# STM32F21x register map
File version: 1.0
CPU: 
Registers are 32-bit, read-write, reset 0x0 unless marked. A register's access mark holds for its fields unless they carry their own. Offsets are from the block's base; [hi:lo] are bit positions.

## Ethernet_PTP — Ethernet: Precision time protocol
Base 0x40028700
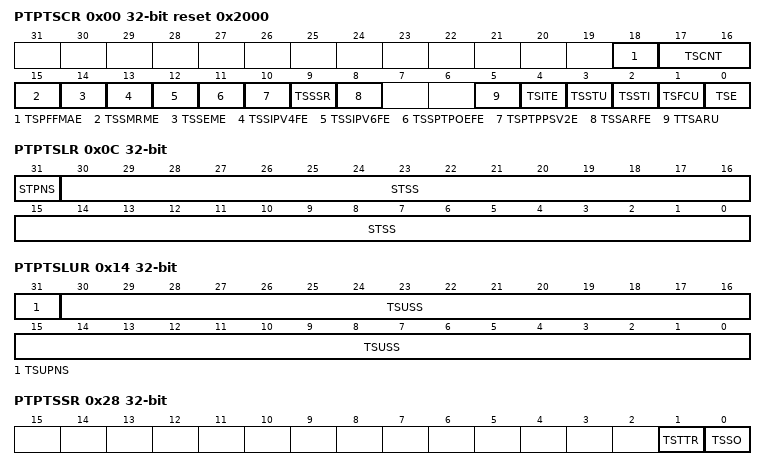
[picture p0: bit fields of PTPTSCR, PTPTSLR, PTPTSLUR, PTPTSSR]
0x00 PTPTSCR reset 0x2000 — Ethernet PTP time stamp control register
  [18] TSPFFMAE — Time stamp PTP frame filtering MAC address enable
  [17:16] TSCNT — Time stamp clock node type
  [15] TSSMRME — Time stamp snapshot for message relevant to master enable
  [14] TSSEME — Time stamp snapshot for event message enable
  [13] TSSIPV4FE — Time stamp snapshot for IPv4 frames enable
  [12] TSSIPV6FE — Time stamp snapshot for IPv6 frames enable
  [11] TSSPTPOEFE — Time stamp snapshot for PTP over ethernet frames enable
  [10] TSPTPPSV2E — Time stamp PTP packet snooping for version2 format enable
  [9] TSSSR — Time stamp subsecond rollover: digital or binary rollover control
  [8] TSSARFE — Time stamp snapshot for all received frames enable
  [5] TTSARU — Time stamp addend register update
  [4] TSITE — Time stamp interrupt trigger enable
  [3] TSSTU — Time stamp system time update
  [2] TSSTI — Time stamp system time initialize
  [1] TSFCU — Time stamp fine or coarse update
  [0] TSE — Time stamp enable
0x04 PTPSSIR — Ethernet PTP subsecond increment register
  [7:0] STSSI — System time subsecond increment
0x08 PTPTSHR ro — Ethernet PTP time stamp high register
  [31:0] STS — System time second
0x0C PTPTSLR ro — Ethernet PTP time stamp low register
  [31] STPNS — System time positive or negative sign
  [30:0] STSS — System time subseconds
0x10 PTPTSHUR — Ethernet PTP time stamp high update register
  [31:0] TSUS — Time stamp update second
0x14 PTPTSLUR — Ethernet PTP time stamp low update register
  [31] TSUPNS — Time stamp update positive or negative sign
  [30:0] TSUSS — Time stamp update subseconds
0x18 PTPTSAR — Ethernet PTP time stamp addend register
  [31:0] TSA — Time stamp addend
0x1C PTPTTHR — Ethernet PTP target time high register
  [31:0] TTSH — Target time stamp high
0x20 PTPTTLR — Ethernet PTP target time low register
  [31:0] TTSL — Target time stamp low
0x28 PTPTSSR ro — Ethernet PTP time stamp status register
  [1] TSTTR — Time stamp target time reached
  [0] TSSO — Time stamp second overflow
0x2C PTPPPSCR ro — Ethernet PTP PPS control register
  [3:0] PPSFREQ — PPS frequency selection

## Ethernet_DMA — Ethernet: DMA controller operation
Base 0x40029000
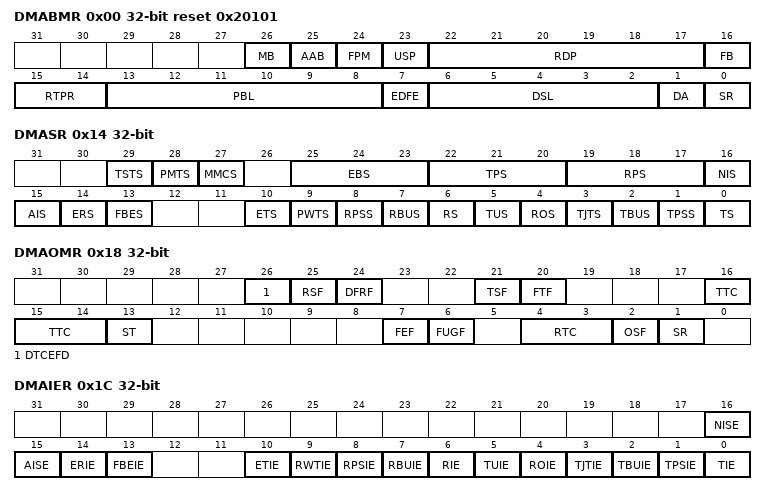
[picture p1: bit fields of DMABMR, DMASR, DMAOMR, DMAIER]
0x00 DMABMR reset 0x20101 — Ethernet DMA bus mode register
  [26] MB — Mixed burst
  [25] AAB — Address-aligned beats
  [24] FPM — 4xPBL mode
  [23] USP — Use separate PBL
  [22:17] RDP — Rx DMA PBL
  [16] FB — Fixed burst
  [15:14] RTPR — Rx Tx priority ratio
  [13:8] PBL — Programmable burst length
  [7] EDFE — Enhanced descriptor format enable
  [6:2] DSL — Descriptor skip length
  [1] DA — DMA Arbitration
  [0] SR — Software reset
0x04 DMATPDR — Ethernet DMA transmit poll demand register
  [31:0] TPD — Transmit poll demand
0x08 DMARPDR — EHERNET DMA receive poll demand register
  [31:0] RPD — Receive poll demand
0x0C DMARDLAR — Ethernet DMA receive descriptor list address register
  [31:0] SRL — Start of receive list
0x10 DMATDLAR — Ethernet DMA transmit descriptor list address register
  [31:0] STL — Start of transmit list
0x14 DMASR access per field — Ethernet DMA status register
  [29] TSTS ro — Time stamp trigger status
  [28] PMTS ro — PMT status
  [27] MMCS ro — MMC status
  [25:23] EBS ro — Error bits status
  [22:20] TPS ro — Transmit process state
  [19:17] RPS ro — Receive process state
  [16] NIS rw — Normal interrupt summary
  [15] AIS rw — Abnormal interrupt summary
  [14] ERS rw — Early receive status
  [13] FBES rw — Fatal bus error status
  [10] ETS rw — Early transmit status
  [9] PWTS rw — Receive watchdog timeout status
  [8] RPSS rw — Receive process stopped status
  [7] RBUS rw — Receive buffer unavailable status
  [6] RS rw — Receive status
  [5] TUS rw — Transmit underflow status
  [4] ROS rw — Receive overflow status
  [3] TJTS rw — Transmit jabber timeout status
  [2] TBUS rw — Transmit buffer unavailable status
  [1] TPSS rw — Transmit process stopped status
  [0] TS rw — Transmit status
0x18 DMAOMR — Ethernet DMA operation mode register
  [26] DTCEFD, [25] RSF, [24] DFRF, [21] TSF, [20] FTF, [16:14] TTC, [13] ST, [7] FEF, [6] FUGF, [4:3] RTC, [2] OSF, [1] SR
0x1C DMAIER — Ethernet DMA interrupt enable register
  [16] NISE — Normal interrupt summary enable
  [15] AISE — Abnormal interrupt summary enable
  [14] ERIE — Early receive interrupt enable
  [13] FBEIE — Fatal bus error interrupt enable
  [10] ETIE — Early transmit interrupt enable
  [9] RWTIE — receive watchdog timeout interrupt enable
  [8] RPSIE — Receive process stopped interrupt enable
  [7] RBUIE — Receive buffer unavailable interrupt enable
  [6] RIE — Receive interrupt enable
  [5] TUIE — Underflow interrupt enable
  [4] ROIE — Overflow interrupt enable
  [3] TJTIE — Transmit jabber timeout interrupt enable
  [2] TBUIE — Transmit buffer unavailable interrupt enable
  [1] TPSIE — Transmit process stopped interrupt enable
  [0] TIE — Transmit interrupt enable
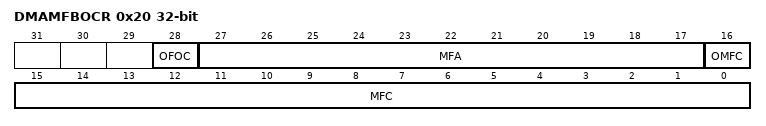
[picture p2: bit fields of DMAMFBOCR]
0x20 DMAMFBOCR — Ethernet DMA missed frame and buffer overflow counter register
  [28] OFOC — Overflow bit for FIFO overflow counter
  [27:17] MFA — Missed frames by the application
  [16] OMFC — Overflow bit for missed frame counter
  [15:0] MFC — Missed frames by the controller
0x24 DMARSWTR — Ethernet DMA receive status watchdog timer register
  [7:0] RSWTC — Receive status watchdog timer count
0x48 DMACHTDR ro — Ethernet DMA current host transmit descriptor register
  [31:0] HTDAP — Host transmit descriptor address pointer
0x4C DMACHRDR ro — Ethernet DMA current host receive descriptor register
  [31:0] HRDAP — Host receive descriptor address pointer
0x50 DMACHTBAR ro — Ethernet DMA current host transmit buffer address register
  [31:0] HTBAP — Host transmit buffer address pointer
0x54 DMACHRBAR ro — Ethernet DMA current host receive buffer address register
  [31:0] HRBAP — Host receive buffer address pointer
